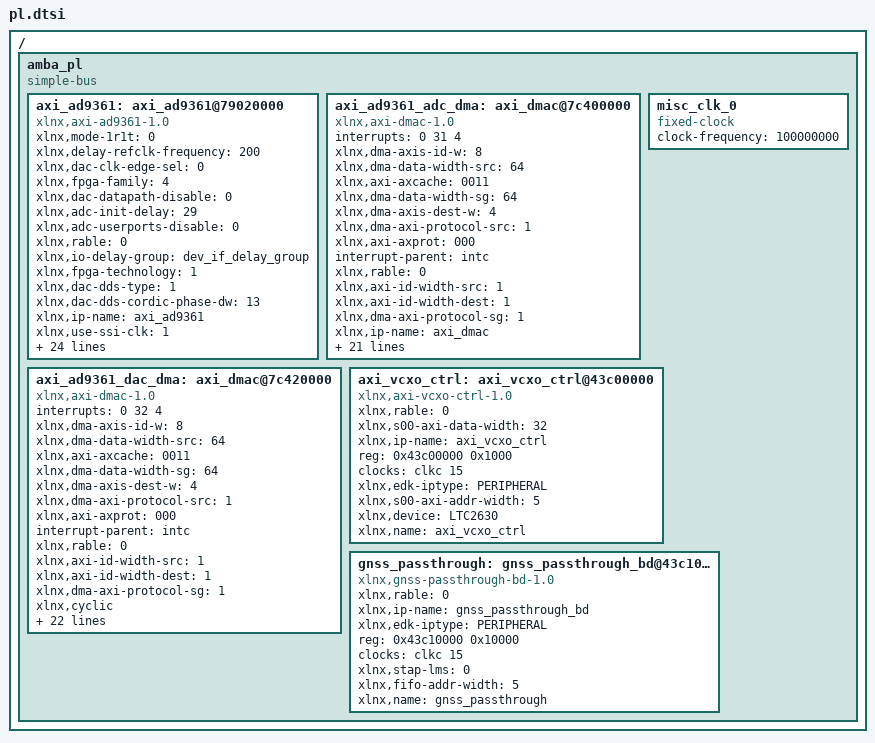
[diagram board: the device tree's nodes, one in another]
/ {
	amba_pl: amba_pl {
		ranges;
		compatible = "simple-bus";
		#address-cells = <1>;
		#size-cells = <1>;
		axi_ad9361: axi_ad9361@79020000 {
			xlnx,mode-1r1t = <0>;
			xlnx,delay-refclk-frequency = <200>;
			xlnx,dac-clk-edge-sel = <0>;
			compatible = "xlnx,axi-ad9361-1.0";
			xlnx,fpga-family = <4>;
			xlnx,dac-datapath-disable = <0>;
			xlnx,adc-init-delay = <29>;
			xlnx,adc-userports-disable = <0>;
			xlnx,rable = <0>;
			xlnx,io-delay-group = "dev_if_delay_group";
			xlnx,fpga-technology = <1>;
			xlnx,dac-dds-type = <1>;
			xlnx,dac-dds-cordic-phase-dw = <13>;
			xlnx,ip-name = "axi_ad9361";
			xlnx,use-ssi-clk = <1>;
			xlnx,dev-package = <14>;
			reg = <0x79020000 0x10000>;
			xlnx,adc-iqcorrection-disable = <0>;
			clocks = <&misc_clk_0>, <&clkc 16>, <&clkc 15>;
			xlnx,speed-grade = <20>;
			xlnx,pps-receiver-enable = <0>;
			xlnx,iodelay-ctrl = <1>;
			xlnx,dac-dds-cordic-dw = <14>;
			xlnx,cmos-or-lvds-n = <0>;
			xlnx,adc-dcfilter-disable = <0>;
			xlnx,edk-iptype = "PERIPHERAL";
			xlnx,tdd-disable = <1>;
			xlnx,id = <0>;
			xlnx,dac-userports-disable = <0>;
			xlnx,dac-init-delay = <0>;
			xlnx,adc-datapath-disable = <0>;
			xlnx,mimo-enable = <0>;
			xlnx,dac-dds-phase-dw = <16>;
			status = "okay";
			clock-names = "clk" , "delay_clk" , "s_axi_aclk";
			xlnx,dac-iqcorrection-disable = <0>;
			xlnx,dac-iodelay-enable = <0>;
			xlnx,rx-nodpa = <0>;
			xlnx,dac-dds-disable = <0>;
			xlnx,name = "axi_ad9361";
			xlnx,adc-dataformat-disable = <0>;
		};
		axi_ad9361_adc_dma: axi_dmac@7c400000 {
			interrupts = < 0 31 4 >;
			xlnx,dma-axis-id-w = <8>;
			compatible = "xlnx,axi-dmac-1.0";
			xlnx,dma-data-width-src = <64>;
			xlnx,axi-axcache = "0011";
			xlnx,dma-data-width-sg = <64>;
			xlnx,dma-axis-dest-w = <4>;
			xlnx,dma-axi-protocol-src = <1>;
			xlnx,axi-axprot = "000";
			interrupt-parent = <&intc>;
			xlnx,rable = <0>;
			xlnx,axi-id-width-src = <1>;
			xlnx,axi-id-width-dest = <1>;
			xlnx,dma-axi-protocol-sg = <1>;
			xlnx,ip-name = "axi_dmac";
			reg = <0x7c400000 0x1000>;
			clocks = <&misc_clk_0>, <&clkc 15>, <&clkc 15>;
			xlnx,async-clk-dest-sg;
			xlnx,async-clk-src-sg;
			xlnx,allow-asym-mem = <1>;
			xlnx,max-bytes-per-burst = <128>;
			xlnx,dma-data-width-dest = <64>;
			xlnx,fifo-size = <8>;
			xlnx,edk-iptype = "PERIPHERAL";
			xlnx,id = <0>;
			xlnx,dma-axi-protocol-dest = <1>;
			xlnx,dma-type-src = <2>;
			xlnx,dma-type-dest = <0>;
			xlnx,dma-length-width = <24>;
			xlnx,dma-axi-addr-width = <30>;
			status = "okay";
			clock-names = "fifo_wr_clk" , "m_dest_axi_aclk" , "s_axi_aclk";
			xlnx,axis-tuser-sync;
			xlnx,async-clk-req-src;
			xlnx,async-clk-src-dest;
			interrupt-names = "irq";
			xlnx,axi-id-width-sg = <1>;
			xlnx,name = "axi_ad9361_adc_dma";
			xlnx,async-clk-req-sg;
		};
		axi_ad9361_dac_dma: axi_dmac@7c420000 {
			interrupts = < 0 32 4 >;
			xlnx,dma-axis-id-w = <8>;
			compatible = "xlnx,axi-dmac-1.0";
			xlnx,dma-data-width-src = <64>;
			xlnx,axi-axcache = "0011";
			xlnx,dma-data-width-sg = <64>;
			xlnx,dma-axis-dest-w = <4>;
			xlnx,dma-axi-protocol-src = <1>;
			xlnx,axi-axprot = "000";
			interrupt-parent = <&intc>;
			xlnx,rable = <0>;
			xlnx,axi-id-width-src = <1>;
			xlnx,axi-id-width-dest = <1>;
			xlnx,dma-axi-protocol-sg = <1>;
			xlnx,cyclic;
			xlnx,ip-name = "axi_dmac";
			reg = <0x7c420000 0x1000>;
			clocks = <&misc_clk_0>, <&clkc 15>, <&clkc 15>;
			xlnx,async-clk-dest-sg;
			xlnx,async-clk-src-sg;
			xlnx,allow-asym-mem = <1>;
			xlnx,max-bytes-per-burst = <128>;
			xlnx,dma-data-width-dest = <64>;
			xlnx,fifo-size = <8>;
			xlnx,edk-iptype = "PERIPHERAL";
			xlnx,id = <0>;
			xlnx,dma-axi-protocol-dest = <1>;
			xlnx,dma-type-src = <0>;
			xlnx,dma-type-dest = <1>;
			xlnx,dma-length-width = <24>;
			xlnx,dma-axi-addr-width = <30>;
			status = "okay";
			clock-names = "m_axis_aclk" , "m_src_axi_aclk" , "s_axi_aclk";
			xlnx,axis-tuser-sync;
			xlnx,async-clk-dest-req;
			xlnx,async-clk-src-dest;
			interrupt-names = "irq";
			xlnx,axi-id-width-sg = <1>;
			xlnx,name = "axi_ad9361_dac_dma";
			xlnx,async-clk-req-sg;
		};
		misc_clk_0: misc_clk_0 {
			compatible = "fixed-clock";
			clock-frequency = <100000000>;
			#clock-cells = <0>;
		};
		axi_vcxo_ctrl: axi_vcxo_ctrl@43c00000 {
			compatible = "xlnx,axi-vcxo-ctrl-1.0";
			xlnx,rable = <0>;
			xlnx,s00-axi-data-width = <32>;
			xlnx,ip-name = "axi_vcxo_ctrl";
			reg = <0x43c00000 0x1000>;
			clocks = <&clkc 15>;
			xlnx,edk-iptype = "PERIPHERAL";
			status = "okay";
			xlnx,s00-axi-addr-width = <5>;
			clock-names = "s00_axi_aclk";
			xlnx,device = "LTC2630";
			xlnx,name = "axi_vcxo_ctrl";
		};
		gnss_passthrough: gnss_passthrough_bd@43c10000 {
			xlnx,rable = <0>;
			compatible = "xlnx,gnss-passthrough-bd-1.0";
			status = "okay";
			clock-names = "s_axi_aclk";
			xlnx,ip-name = "gnss_passthrough_bd";
			xlnx,edk-iptype = "PERIPHERAL";
			reg = <0x43c10000 0x10000>;
			clocks = <&clkc 15>;
			xlnx,stap-lms = <0>;
			xlnx,fifo-addr-width = <5>;
			xlnx,name = "gnss_passthrough";
		};
	};
};
